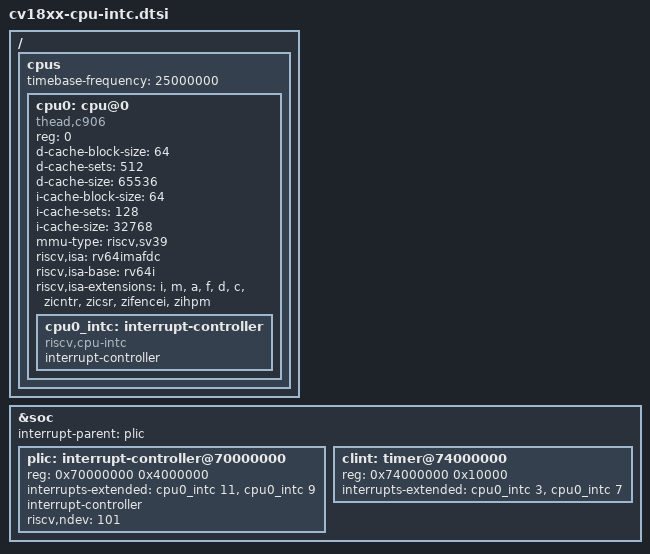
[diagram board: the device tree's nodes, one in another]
// SPDX-License-Identifier: (GPL-2.0 OR MIT)
/*
 * Copyright (C) 2023 Jisheng Zhang <jszhang@kernel.org>
 * Copyright (C) 2023 Inochi Amaoto <inochiama@outlook.com>
 */

/ {
	cpus: cpus {
		#address-cells = <1>;
		#size-cells = <0>;
		timebase-frequency = <25000000>;

		cpu0: cpu@0 {
			compatible = "thead,c906", "riscv";
			device_type = "cpu";
			reg = <0>;
			d-cache-block-size = <64>;
			d-cache-sets = <512>;
			d-cache-size = <65536>;
			i-cache-block-size = <64>;
			i-cache-sets = <128>;
			i-cache-size = <32768>;
			mmu-type = "riscv,sv39";
			riscv,isa = "rv64imafdc";
			riscv,isa-base = "rv64i";
			riscv,isa-extensions = "i", "m", "a", "f", "d", "c", "zicntr", "zicsr",
					       "zifencei", "zihpm";

			cpu0_intc: interrupt-controller {
				compatible = "riscv,cpu-intc";
				interrupt-controller;
				#interrupt-cells = <1>;
			};
		};
	};
};

&soc {
	interrupt-parent = <&plic>;

	plic: interrupt-controller@70000000 {
		reg = <0x70000000 0x4000000>;
		interrupts-extended = <&cpu0_intc 11>, <&cpu0_intc 9>;
		interrupt-controller;
		#address-cells = <0>;
		#interrupt-cells = <2>;
		riscv,ndev = <101>;
	};

	clint: timer@74000000 {
		reg = <0x74000000 0x10000>;
		interrupts-extended = <&cpu0_intc 3>, <&cpu0_intc 7>;
	};
};
